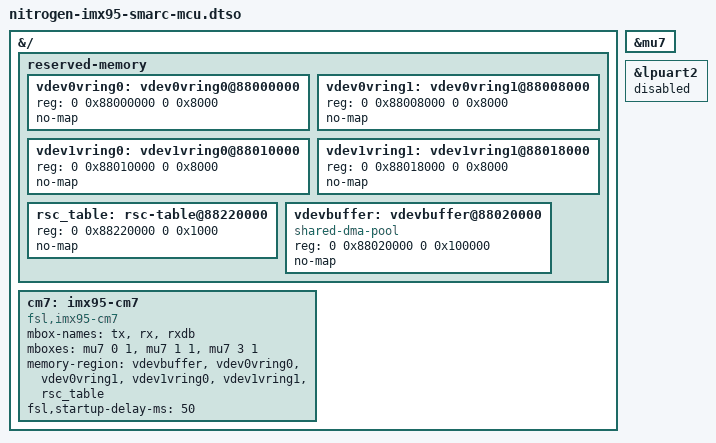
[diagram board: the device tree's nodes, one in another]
// SPDX-License-Identifier: (GPL-2.0+ OR MIT)
/*
 * Copyright 2024 Ezurio LLC
 */

/dts-v1/;
/plugin/;

&{/} {
	reserved-memory {
		#address-cells = <2>;
		#size-cells = <2>;

		vdev0vring0: vdev0vring0@88000000 {
			reg = <0 0x88000000 0 0x8000>;
			no-map;
		};

		vdev0vring1: vdev0vring1@88008000 {
			reg = <0 0x88008000 0 0x8000>;
			no-map;
		};

		vdev1vring0: vdev1vring0@88010000 {
			reg = <0 0x88010000 0 0x8000>;
			no-map;
		};

		vdev1vring1: vdev1vring1@88018000 {
			reg = <0 0x88018000 0 0x8000>;
			no-map;
		};

		rsc_table: rsc-table@88220000 {
			reg = <0 0x88220000 0 0x1000>;
			no-map;
		};

		vdevbuffer: vdevbuffer@88020000 {
			compatible = "shared-dma-pool";
			reg = <0 0x88020000 0 0x100000>;
			no-map;
		};
	};

	cm7: imx95-cm7 {
		compatible = "fsl,imx95-cm7";
		mbox-names = "tx", "rx", "rxdb";
		mboxes = <&mu7 0 1
			  &mu7 1 1
			  &mu7 3 1>;
		memory-region = <&vdevbuffer>, <&vdev0vring0>, <&vdev0vring1>,
				<&vdev1vring0>, <&vdev1vring1>, <&rsc_table>;
		fsl,startup-delay-ms = <50>;
		status = "okay";
	};
};

&mu7 {
	status = "okay";
};


&lpuart2 {
	status = "disabled";
};
